# STM32F105VCT7 register map
File version: 1.0
Registers are 32-bit, access not given, reset 0x0 unless marked. A register's access mark holds for its fields unless they carry their own. Offsets are from the block's base; [hi:lo] are bit positions; {n}, {i} and the like mark numbered series.

## CAN1
Base 0x40006400
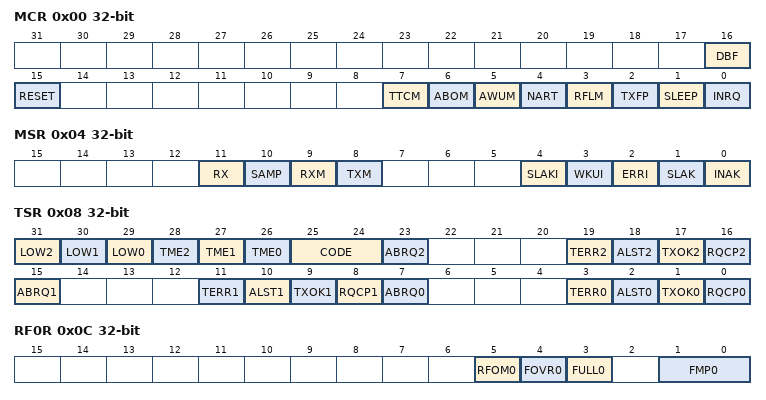
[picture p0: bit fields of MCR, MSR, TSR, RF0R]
0x00 MCR
  [16] DBF, [15] RESET, [7] TTCM, [6] ABOM, [5] AWUM, [4] NART, [3] RFLM, [2] TXFP, [1] SLEEP, [0] INRQ
0x04 MSR
  [11] RX, [10] SAMP, [9] RXM, [8] TXM, [4] SLAKI, [3] WKUI, [2] ERRI, [1] SLAK, [0] INAK
0x08 TSR
  [31] LOW2, [30] LOW1, [29] LOW0, [28] TME2, [27] TME1, [26] TME0, [25:24] CODE, [23] ABRQ2, [19] TERR2, [18] ALST2, [17] TXOK2, [16] RQCP2, [15] ABRQ1, [11] TERR1, [10] ALST1, [9] TXOK1, [8] RQCP1, [7] ABRQ0, [3] TERR0, [2] ALST0, [1] TXOK0, [0] RQCP0
0x0C RF0R
  [5] RFOM0, [4] FOVR0, [3] FULL0, [1:0] FMP0
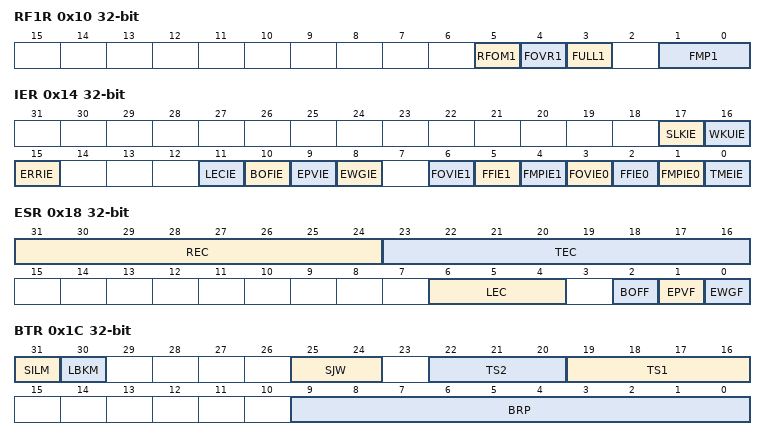
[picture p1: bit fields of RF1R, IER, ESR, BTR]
0x10 RF1R
  [5] RFOM1, [4] FOVR1, [3] FULL1, [1:0] FMP1
0x14 IER
  [17] SLKIE, [16] WKUIE, [15] ERRIE, [11] LECIE, [10] BOFIE, [9] EPVIE, [8] EWGIE, [6] FOVIE1, [5] FFIE1, [4] FMPIE1, [3] FOVIE0, [2] FFIE0, [1] FMPIE0, [0] TMEIE
0x18 ESR
  [31:24] REC, [23:16] TEC, [6:4] LEC, [2] BOFF, [1] EPVF, [0] EWGF
0x1C BTR
  [31] SILM, [30] LBKM, [25:24] SJW, [22:20] TS2, [19:16] TS1, [9:0] BRP
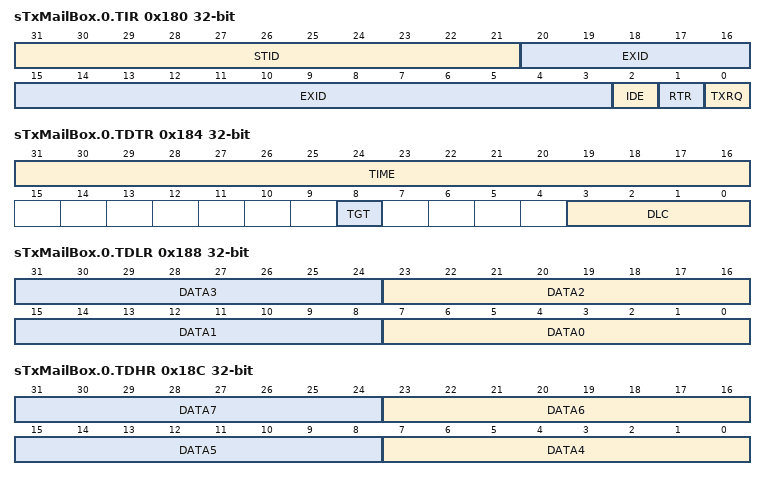
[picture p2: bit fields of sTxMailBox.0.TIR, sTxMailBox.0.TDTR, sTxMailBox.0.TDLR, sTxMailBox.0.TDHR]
0x180 sTxMailBox.0.TIR
  [31:21] STID, [20:3] EXID, [2] IDE, [1] RTR, [0] TXRQ
0x184 sTxMailBox.0.TDTR
  [31:16] TIME, [8] TGT, [3:0] DLC
0x188 sTxMailBox.0.TDLR
  [8n+7:8n] DATA{n} (n=0..3)
0x18C sTxMailBox.0.TDHR
  [8n-25:8n-32] DATA{n} (n=4..7)
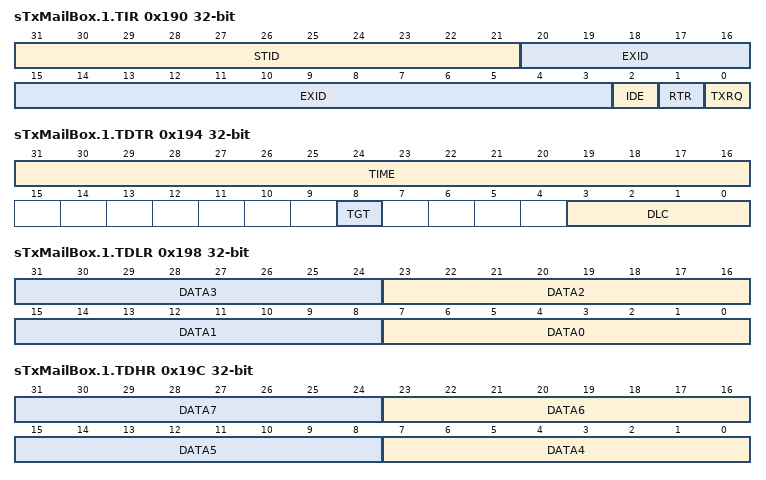
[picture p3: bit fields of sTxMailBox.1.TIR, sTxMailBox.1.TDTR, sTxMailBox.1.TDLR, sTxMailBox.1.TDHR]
0x190 sTxMailBox.1.TIR
  [31:21] STID, [20:3] EXID, [2] IDE, [1] RTR, [0] TXRQ
0x194 sTxMailBox.1.TDTR
  [31:16] TIME, [8] TGT, [3:0] DLC
0x198 sTxMailBox.1.TDLR
  [8n+7:8n] DATA{n} (n=0..3)
0x19C sTxMailBox.1.TDHR
  [8n-25:8n-32] DATA{n} (n=4..7)
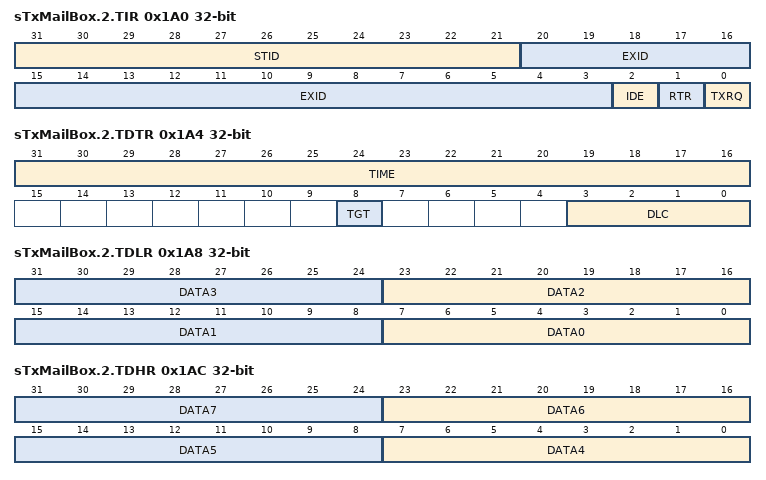
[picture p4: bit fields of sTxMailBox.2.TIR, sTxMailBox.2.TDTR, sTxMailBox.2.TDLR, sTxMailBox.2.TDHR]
0x1A0 sTxMailBox.2.TIR
  [31:21] STID, [20:3] EXID, [2] IDE, [1] RTR, [0] TXRQ
0x1A4 sTxMailBox.2.TDTR
  [31:16] TIME, [8] TGT, [3:0] DLC
0x1A8 sTxMailBox.2.TDLR
  [8n+7:8n] DATA{n} (n=0..3)
0x1AC sTxMailBox.2.TDHR
  [8n-25:8n-32] DATA{n} (n=4..7)
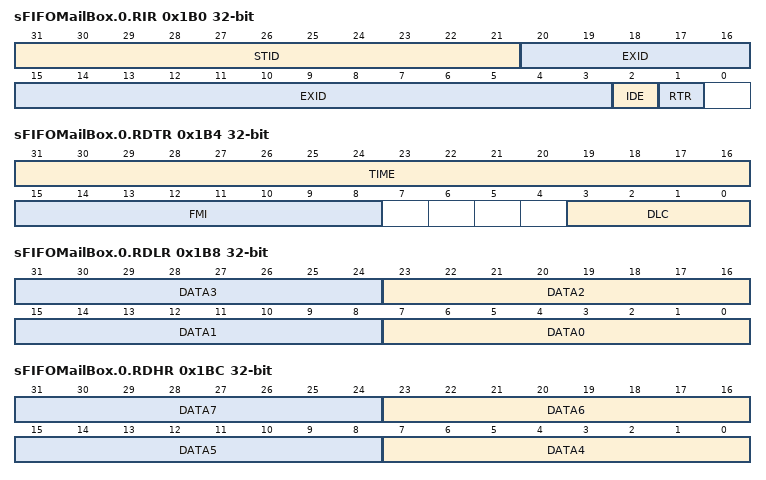
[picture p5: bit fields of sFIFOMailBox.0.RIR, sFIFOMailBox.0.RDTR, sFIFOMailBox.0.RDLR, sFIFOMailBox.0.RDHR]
0x1B0 sFIFOMailBox.0.RIR
  [31:21] STID, [20:3] EXID, [2] IDE, [1] RTR
0x1B4 sFIFOMailBox.0.RDTR
  [31:16] TIME, [15:8] FMI, [3:0] DLC
0x1B8 sFIFOMailBox.0.RDLR
  [8n+7:8n] DATA{n} (n=0..3)
0x1BC sFIFOMailBox.0.RDHR
  [8n-25:8n-32] DATA{n} (n=4..7)
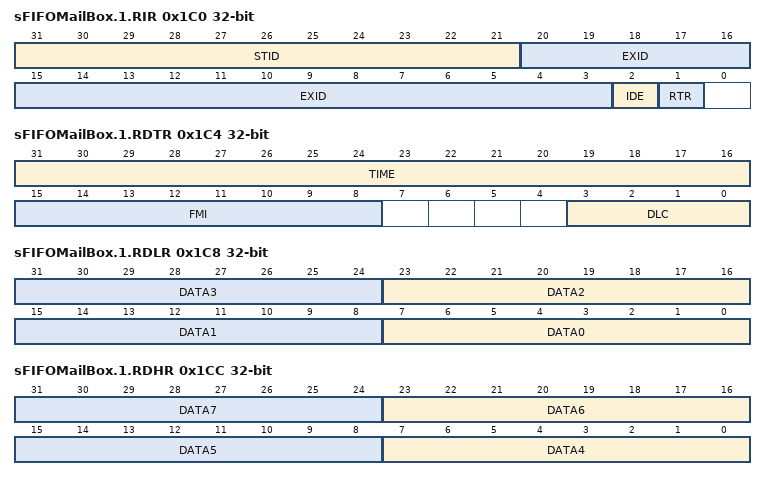
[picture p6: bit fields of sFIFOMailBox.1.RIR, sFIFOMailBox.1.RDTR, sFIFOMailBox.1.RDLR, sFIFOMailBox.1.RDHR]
0x1C0 sFIFOMailBox.1.RIR
  [31:21] STID, [20:3] EXID, [2] IDE, [1] RTR
0x1C4 sFIFOMailBox.1.RDTR
  [31:16] TIME, [15:8] FMI, [3:0] DLC
0x1C8 sFIFOMailBox.1.RDLR
  [8n+7:8n] DATA{n} (n=0..3)
0x1CC sFIFOMailBox.1.RDHR
  [8n-25:8n-32] DATA{n} (n=4..7)
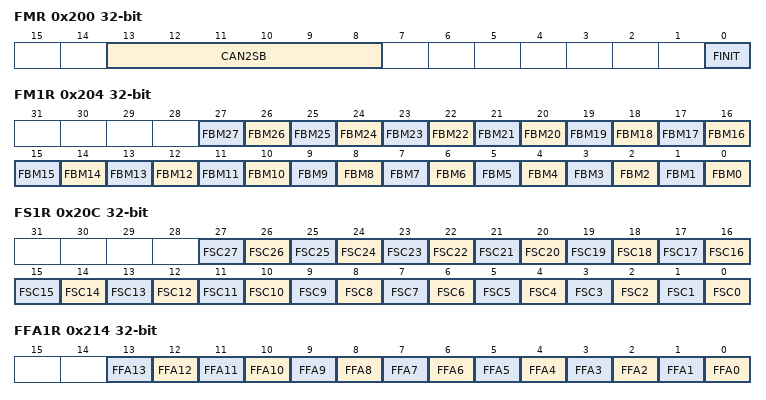
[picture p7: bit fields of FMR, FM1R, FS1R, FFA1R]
0x200 FMR
  [13:8] CAN2SB, [0] FINIT
0x204 FM1R
  [n] FBM{n} (n=0..27)
0x20C FS1R
  [n] FSC{n} (n=0..27)
0x214 FFA1R
  [n] FFA{n} (n=0..13)
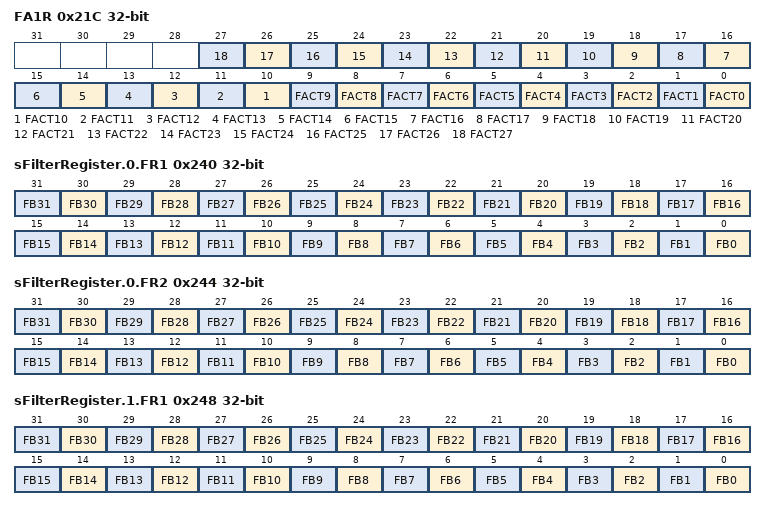
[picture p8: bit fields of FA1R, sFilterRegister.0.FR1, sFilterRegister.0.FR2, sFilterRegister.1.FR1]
0x21C FA1R
  [n] FACT{n} (n=0..27)
0x240 sFilterRegister.0.FR1
  [n] FB{n} (n=0..31)
0x244 sFilterRegister.0.FR2
  [n] FB{n} (n=0..31)
0x248 sFilterRegister.1.FR1
  [n] FB{n} (n=0..31)
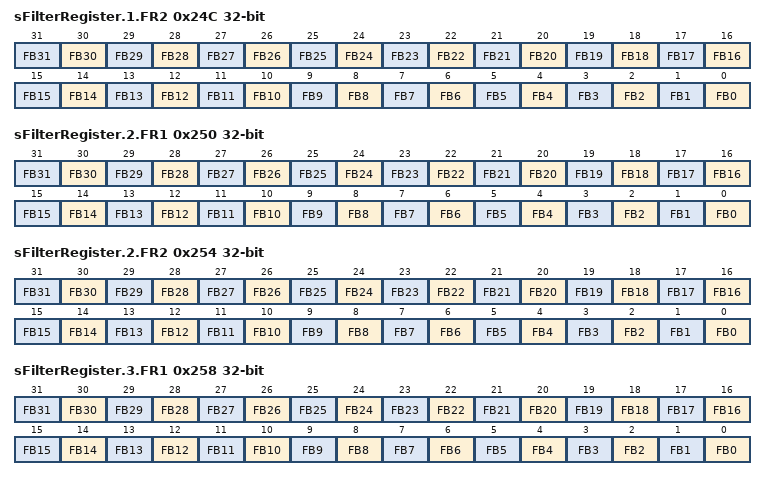
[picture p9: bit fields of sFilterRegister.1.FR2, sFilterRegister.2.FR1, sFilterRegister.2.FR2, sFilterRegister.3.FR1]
0x24C sFilterRegister.1.FR2
  [n] FB{n} (n=0..31)
0x250 sFilterRegister.2.FR1
  [n] FB{n} (n=0..31)
0x254 sFilterRegister.2.FR2
  [n] FB{n} (n=0..31)
0x258 sFilterRegister.3.FR1
  [n] FB{n} (n=0..31)
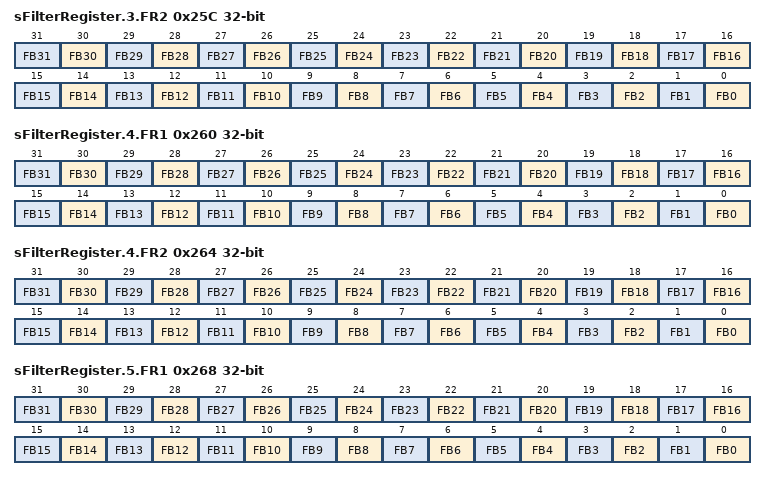
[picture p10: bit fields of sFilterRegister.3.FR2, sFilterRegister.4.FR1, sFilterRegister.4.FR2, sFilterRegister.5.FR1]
0x25C sFilterRegister.3.FR2
  [n] FB{n} (n=0..31)
0x260 sFilterRegister.4.FR1
  [n] FB{n} (n=0..31)
0x264 sFilterRegister.4.FR2
  [n] FB{n} (n=0..31)
0x268 sFilterRegister.5.FR1
  [n] FB{n} (n=0..31)
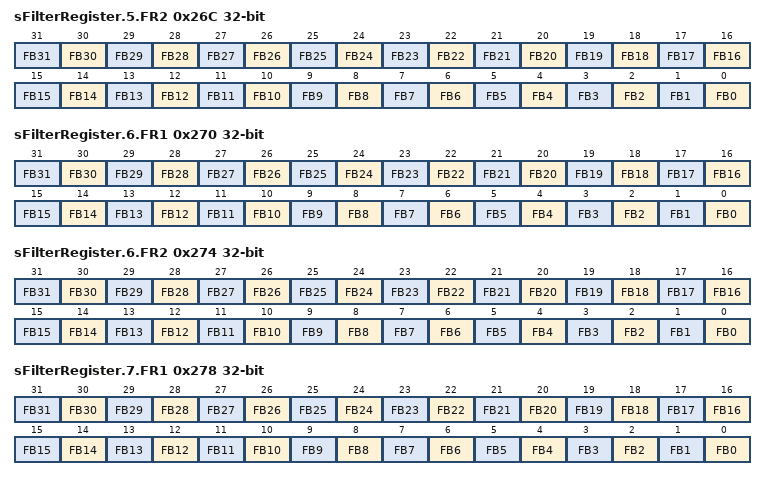
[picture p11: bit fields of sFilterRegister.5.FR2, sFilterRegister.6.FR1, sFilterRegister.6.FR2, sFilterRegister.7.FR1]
0x26C sFilterRegister.5.FR2
  [n] FB{n} (n=0..31)
0x270 sFilterRegister.6.FR1
  [n] FB{n} (n=0..31)
0x274 sFilterRegister.6.FR2
  [n] FB{n} (n=0..31)
0x278 sFilterRegister.7.FR1
  [n] FB{n} (n=0..31)
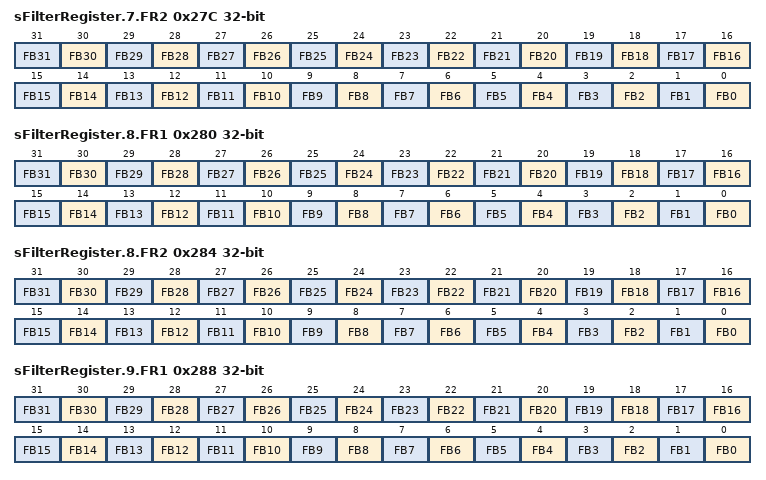
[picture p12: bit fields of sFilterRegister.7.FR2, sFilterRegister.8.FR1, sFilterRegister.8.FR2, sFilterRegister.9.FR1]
0x27C sFilterRegister.7.FR2
  [n] FB{n} (n=0..31)
0x280 sFilterRegister.8.FR1
  [n] FB{n} (n=0..31)
0x284 sFilterRegister.8.FR2
  [n] FB{n} (n=0..31)
0x288 sFilterRegister.9.FR1
  [n] FB{n} (n=0..31)
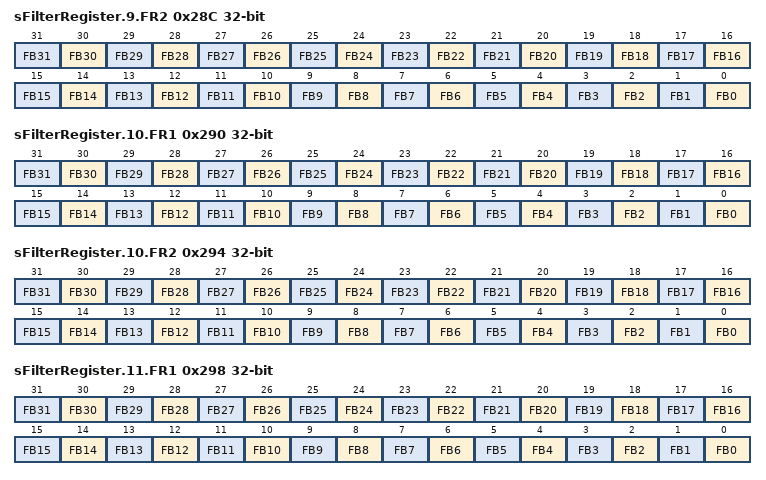
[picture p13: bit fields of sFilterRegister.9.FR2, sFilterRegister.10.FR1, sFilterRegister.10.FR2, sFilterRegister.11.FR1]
0x28C sFilterRegister.9.FR2
  [n] FB{n} (n=0..31)
0x290 sFilterRegister.10.FR1
  [n] FB{n} (n=0..31)
0x294 sFilterRegister.10.FR2
  [n] FB{n} (n=0..31)
0x298 sFilterRegister.11.FR1
  [n] FB{n} (n=0..31)
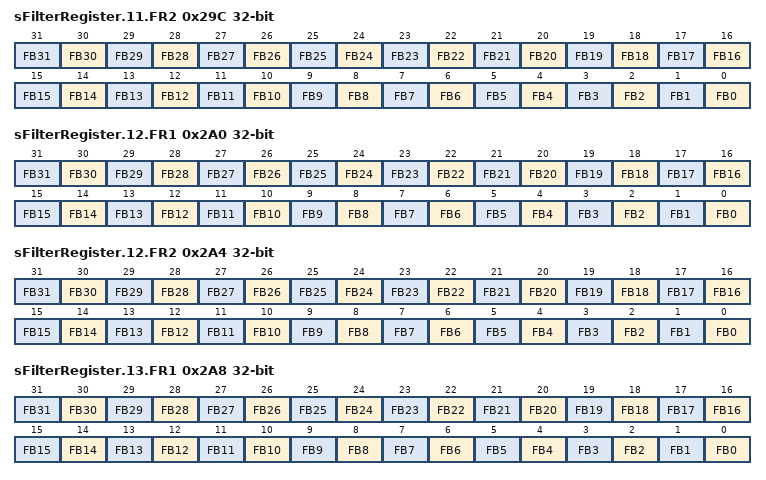
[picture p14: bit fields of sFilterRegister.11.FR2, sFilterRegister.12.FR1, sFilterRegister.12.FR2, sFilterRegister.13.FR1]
0x29C sFilterRegister.11.FR2
  [n] FB{n} (n=0..31)
0x2A0 sFilterRegister.12.FR1
  [n] FB{n} (n=0..31)
0x2A4 sFilterRegister.12.FR2
  [n] FB{n} (n=0..31)
0x2A8 sFilterRegister.13.FR1
  [n] FB{n} (n=0..31)
0x2AC sFilterRegister.13.FR2
  [n] FB{n} (n=0..31)
0x2B0 sFilterRegister.14.FR1
  [n] FB{n} (n=0..31)
0x2B4 sFilterRegister.14.FR2
  [n] FB{n} (n=0..31)
0x2B8 sFilterRegister.15.FR1
  [n] FB{n} (n=0..31)
0x2BC sFilterRegister.15.FR2
  [n] FB{n} (n=0..31)
0x2C0 sFilterRegister.16.FR1
  [n] FB{n} (n=0..31)
0x2C4 sFilterRegister.16.FR2
  [n] FB{n} (n=0..31)
0x2C8 sFilterRegister.17.FR1
  [n] FB{n} (n=0..31)
0x2CC sFilterRegister.17.FR2
  [n] FB{n} (n=0..31)
0x2D0 sFilterRegister.18.FR1
  [n] FB{n} (n=0..31)
0x2D4 sFilterRegister.18.FR2
  [n] FB{n} (n=0..31)
0x2D8 sFilterRegister.19.FR1
  [n] FB{n} (n=0..31)
0x2DC sFilterRegister.19.FR2
  [n] FB{n} (n=0..31)
0x2E0 sFilterRegister.20.FR1
  [n] FB{n} (n=0..31)
0x2E4 sFilterRegister.20.FR2
  [n] FB{n} (n=0..31)
0x2E8 sFilterRegister.21.FR1
  [n] FB{n} (n=0..31)
0x2EC sFilterRegister.21.FR2
  [n] FB{n} (n=0..31)
0x2F0 sFilterRegister.22.FR1
  [n] FB{n} (n=0..31)
0x2F4 sFilterRegister.22.FR2
  [n] FB{n} (n=0..31)
0x2F8 sFilterRegister.23.FR1
  [n] FB{n} (n=0..31)
0x2FC sFilterRegister.23.FR2
  [n] FB{n} (n=0..31)
0x300 sFilterRegister.24.FR1
  [n] FB{n} (n=0..31)
0x304 sFilterRegister.24.FR2
  [n] FB{n} (n=0..31)
0x308 sFilterRegister.25.FR1
  [n] FB{n} (n=0..31)
0x30C sFilterRegister.25.FR2
  [n] FB{n} (n=0..31)
0x310 sFilterRegister.26.FR1
  [n] FB{n} (n=0..31)
0x314 sFilterRegister.26.FR2
  [n] FB{n} (n=0..31)
0x318 sFilterRegister.27.FR1
  [n] FB{n} (n=0..31)
0x31C sFilterRegister.27.FR2
  [n] FB{n} (n=0..31)

## CAN2
Base 0x40006800
Registers as CAN1; these are added or differ:
0x200 FMR
  [13:8] CAN2SB, [0] FINIT
